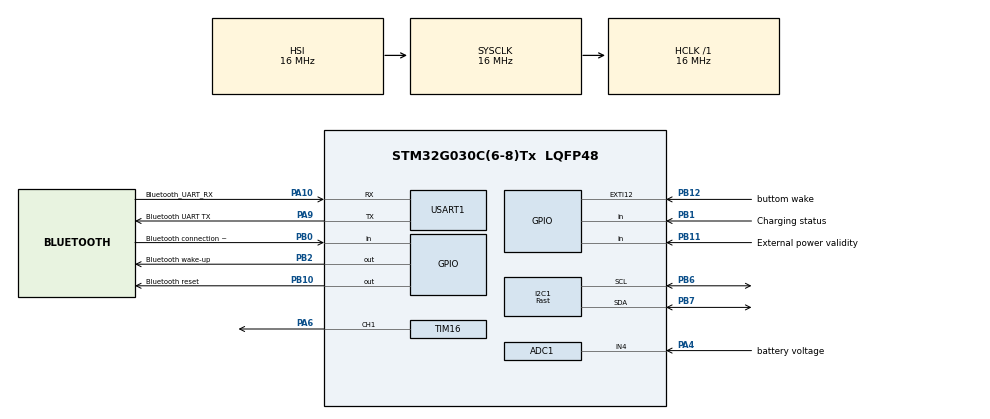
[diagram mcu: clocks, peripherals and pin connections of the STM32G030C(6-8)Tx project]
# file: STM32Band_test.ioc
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ADC1.Channel-0\#ChannelRegularConversion=ADC_CHANNEL_4
ADC1.NbrOfConversionFlag=1
ADC1.Rank-0\#ChannelRegularConversion=1
ADC1.SamplingTime-0\#ChannelRegularConversion=ADC_SAMPLINGTIME_COMMON_1
ADC1.SamplingTimeCommon1=ADC_SAMPLETIME_39CYCLES_5
ADC1.SelectedChannel=ADC_CHANNEL_4
ADC1.master=1
I2C1.I2C_Speed_Mode=I2C_Fast
I2C1.Timing=0x00300617
Mcu.Family=STM32G0
Mcu.Name=STM32G030C(6-8)Tx
Mcu.Package=LQFP48
NVIC.EXTI4_15_IRQn=true\:0\:0\:false\:false\:true\:true\:true\:true
PA10.GPIO_Label=Bluetooth_UART_RX
PA10.Mode=Asynchronous
PA10.Signal=USART1_RX
PA13.Mode=Serial_Wire
PA13.Signal=SYS_SWDIO
PA14-BOOT0.Mode=Serial_Wire
PA14-BOOT0.Signal=SYS_SWCLK
PA4.GPIO_Label=battery voltage
PA4.Mode=IN4
PA4.Signal=ADC1_IN4
PA6.Signal=S_TIM16_CH1
PA9.GPIO_Label=Bluetooth UART TX
PA9.Mode=Asynchronous
PA9.Signal=USART1_TX
PB0.GPIO_Label=Bluetooth connection status
PB0.Signal=GPIO_Input
PB1.GPIO_Label=Charging status
PB1.Signal=GPIO_Input
PB10.GPIO_Label=Bluetooth reset
PB10.PinState=GPIO_PIN_SET
PB10.Signal=GPIO_Output
PB11.GPIO_Label=External power validity
PB11.Signal=GPIO_Input
PB12.GPIO_Label=buttom wake
PB12.Signal=GPXTI12
PB2.GPIO_Label=Bluetooth wake-up
PB2.PinState=GPIO_PIN_SET
PB2.Signal=GPIO_Output
PB6.Mode=I2C
PB6.Signal=I2C1_SCL
PB7.Mode=I2C
PB7.Signal=I2C1_SDA
ProjectManager.HeapSize=0x200
ProjectManager.StackSize=0x400
ProjectManager.TargetToolchain=EWARM V8.50
RCC.AHBFreq_Value=16000000
RCC.CortexFreq_Value=16000000
RCC.EXTERNAL_CLOCK_VALUE=12288000
RCC.HCLKFreq_Value=16000000
RCC.HSE_VALUE=8000000
RCC.HSI_VALUE=16000000
RCC.LSE_VALUE=32768
RCC.SYSCLKFreq_VALUE=16000000
RCC.VCOOutputFreq_Value=128000000
SH.S_TIM16_CH1.0=TIM16_CH1,PWM Generation1 CH1
TIM16.AutoReloadPreload=TIM_AUTORELOAD_PRELOAD_ENABLE
TIM16.Channel=TIM_CHANNEL_1
TIM16.Period=3199
USART1.VirtualMode-Asynchronous=VM_ASYNC
VP_TIM16_VS_ClockSourceINT.Mode=Enable_Timer
board=custom

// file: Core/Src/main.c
/* USER CODE BEGIN Header */
/**
  ******************************************************************************
  * @file           : main.c
  * @brief          : Main program body
  ******************************************************************************
  * @attention
  *
  * Copyright (c) 2026 STMicroelectronics.
  * All rights reserved.
  *
  * This software is licensed under terms that can be found in the LICENSE file
  * in the root directory of this software component.
  * If no LICENSE file comes with this software, it is provided AS-IS.
  *
  ******************************************************************************
  */
/* USER CODE END Header */
#include "main.h"

  /* USER CODE BEGIN Includes */
#include "test_ble.h"
#include "motor.h"
/* USER CODE END Includes */

ADC_HandleTypeDef hadc1;

I2C_HandleTypeDef hi2c1;

TIM_HandleTypeDef htim16;

UART_HandleTypeDef huart1;

void SystemClock_Config(void);
static void MX_GPIO_Init(void);
static void MX_ADC1_Init(void);
static void MX_I2C1_Init(void);
static void MX_USART1_UART_Init(void);
static void MX_TIM16_Init(void);

int main(void)
{

  /* MCU Configuration--------------------------------------------------------*/

  /* Reset of all peripherals, Initializes the Flash interface and the Systick. */
  HAL_Init();

  /* USER CODE BEGIN Init */
  HAL_Delay(200);
  /* USER CODE END Init */

  /* Configure the system clock */
  SystemClock_Config();

  /* Initialize all configured peripherals */
  MX_GPIO_Init();
  MX_ADC1_Init();
  MX_I2C1_Init();
  MX_USART1_UART_Init();
  MX_TIM16_Init();
  motor_init();
  /* USER CODE BEGIN 2 */
  test_ble_main();
  /* USER CODE END 2 */

  /* Infinite loop */
  while (1)
  {

  }
}

void SystemClock_Config(void)
{
  RCC_OscInitTypeDef RCC_OscInitStruct = {0};
  RCC_ClkInitTypeDef RCC_ClkInitStruct = {0};

  /** Configure the main internal regulator output voltage
  */
  HAL_PWREx_ControlVoltageScaling(PWR_REGULATOR_VOLTAGE_SCALE1);

  /** Initializes the RCC Oscillators according to the specified parameters
  * in the RCC_OscInitTypeDef structure.
  */
  RCC_OscInitStruct.OscillatorType = RCC_OSCILLATORTYPE_HSI;
  RCC_OscInitStruct.HSIState = RCC_HSI_ON;
  RCC_OscInitStruct.HSIDiv = RCC_HSI_DIV1;
  RCC_OscInitStruct.HSICalibrationValue = RCC_HSICALIBRATION_DEFAULT;
  RCC_OscInitStruct.PLL.PLLState = RCC_PLL_NONE;
  if (HAL_RCC_OscConfig(&RCC_OscInitStruct) != HAL_OK)
  {
    Error_Handler();
  }

  /** Initializes the CPU, AHB and APB buses clocks
  */
  RCC_ClkInitStruct.ClockType = RCC_CLOCKTYPE_HCLK|RCC_CLOCKTYPE_SYSCLK
                              |RCC_CLOCKTYPE_PCLK1;
  RCC_ClkInitStruct.SYSCLKSource = RCC_SYSCLKSOURCE_HSI;
  RCC_ClkInitStruct.AHBCLKDivider = RCC_SYSCLK_DIV1;
  RCC_ClkInitStruct.APB1CLKDivider = RCC_HCLK_DIV1;

  if (HAL_RCC_ClockConfig(&RCC_ClkInitStruct, FLASH_LATENCY_0) != HAL_OK)
  {
    Error_Handler();
  }
}

static void MX_ADC1_Init(void)
{

  ADC_ChannelConfTypeDef sConfig = {0};

  /** Configure the global features of the ADC (Clock, Resolution, Data Alignment and number of conversion)
  */
  hadc1.Instance = ADC1;
  hadc1.Init.ClockPrescaler = ADC_CLOCK_SYNC_PCLK_DIV2;
  hadc1.Init.Resolution = ADC_RESOLUTION_12B;
  hadc1.Init.DataAlign = ADC_DATAALIGN_RIGHT;
  hadc1.Init.ScanConvMode = ADC_SCAN_DISABLE;
  hadc1.Init.EOCSelection = ADC_EOC_SINGLE_CONV;
  hadc1.Init.LowPowerAutoWait = DISABLE;
  hadc1.Init.LowPowerAutoPowerOff = DISABLE;
  hadc1.Init.ContinuousConvMode = DISABLE;
  hadc1.Init.NbrOfConversion = 1;
  hadc1.Init.DiscontinuousConvMode = DISABLE;
  hadc1.Init.ExternalTrigConv = ADC_SOFTWARE_START;
  hadc1.Init.ExternalTrigConvEdge = ADC_EXTERNALTRIGCONVEDGE_NONE;
  hadc1.Init.DMAContinuousRequests = DISABLE;
  hadc1.Init.Overrun = ADC_OVR_DATA_PRESERVED;
  hadc1.Init.SamplingTimeCommon1 = ADC_SAMPLETIME_39CYCLES_5;
  hadc1.Init.SamplingTimeCommon2 = ADC_SAMPLETIME_1CYCLE_5;
  hadc1.Init.OversamplingMode = DISABLE;
  hadc1.Init.TriggerFrequencyMode = ADC_TRIGGER_FREQ_HIGH;
  if (HAL_ADC_Init(&hadc1) != HAL_OK)
  {
    Error_Handler();
  }

  /** Configure Regular Channel
  */
  sConfig.Channel = ADC_CHANNEL_4;
  sConfig.Rank = ADC_REGULAR_RANK_1;
  sConfig.SamplingTime = ADC_SAMPLINGTIME_COMMON_1;
  if (HAL_ADC_ConfigChannel(&hadc1, &sConfig) != HAL_OK)
  {
    Error_Handler();
  }

}

static void MX_I2C1_Init(void)
{

  hi2c1.Instance = I2C1;
  hi2c1.Init.Timing = 0x00300617;
  hi2c1.Init.OwnAddress1 = 0;
  hi2c1.Init.AddressingMode = I2C_ADDRESSINGMODE_7BIT;
  hi2c1.Init.DualAddressMode = I2C_DUALADDRESS_DISABLE;
  hi2c1.Init.OwnAddress2 = 0;
  hi2c1.Init.OwnAddress2Masks = I2C_OA2_NOMASK;
  hi2c1.Init.GeneralCallMode = I2C_GENERALCALL_DISABLE;
  hi2c1.Init.NoStretchMode = I2C_NOSTRETCH_DISABLE;
  if (HAL_I2C_Init(&hi2c1) != HAL_OK)
  {
    Error_Handler();
  }

  /** Configure Analogue filter
  */
  if (HAL_I2CEx_ConfigAnalogFilter(&hi2c1, I2C_ANALOGFILTER_ENABLE) != HAL_OK)
  {
    Error_Handler();
  }

  /** Configure Digital filter
  */
  if (HAL_I2CEx_ConfigDigitalFilter(&hi2c1, 0) != HAL_OK)
  {
    Error_Handler();
  }

}

static void MX_TIM16_Init(void)
{

  TIM_OC_InitTypeDef sConfigOC = {0};
  TIM_BreakDeadTimeConfigTypeDef sBreakDeadTimeConfig = {0};

  htim16.Instance = TIM16;
  htim16.Init.Prescaler = 0;
  htim16.Init.CounterMode = TIM_COUNTERMODE_UP;
  htim16.Init.Period = 3199;
  htim16.Init.ClockDivision = TIM_CLOCKDIVISION_DIV1;
  htim16.Init.RepetitionCounter = 0;
  htim16.Init.AutoReloadPreload = TIM_AUTORELOAD_PRELOAD_ENABLE;
  if (HAL_TIM_Base_Init(&htim16) != HAL_OK)
  {
    Error_Handler();
  }
  if (HAL_TIM_PWM_Init(&htim16) != HAL_OK)
  {
    Error_Handler();
  }
  sConfigOC.OCMode = TIM_OCMODE_PWM1;
  sConfigOC.Pulse = 0;
  sConfigOC.OCPolarity = TIM_OCPOLARITY_HIGH;
  sConfigOC.OCNPolarity = TIM_OCNPOLARITY_HIGH;
  sConfigOC.OCFastMode = TIM_OCFAST_DISABLE;
  sConfigOC.OCIdleState = TIM_OCIDLESTATE_RESET;
  sConfigOC.OCNIdleState = TIM_OCNIDLESTATE_RESET;
  if (HAL_TIM_PWM_ConfigChannel(&htim16, &sConfigOC, TIM_CHANNEL_1) != HAL_OK)
  {
    Error_Handler();
  }
  sBreakDeadTimeConfig.OffStateRunMode = TIM_OSSR_DISABLE;
  sBreakDeadTimeConfig.OffStateIDLEMode = TIM_OSSI_DISABLE;
  sBreakDeadTimeConfig.LockLevel = TIM_LOCKLEVEL_OFF;
  sBreakDeadTimeConfig.DeadTime = 0;
  sBreakDeadTimeConfig.BreakState = TIM_BREAK_DISABLE;
  sBreakDeadTimeConfig.BreakPolarity = TIM_BREAKPOLARITY_HIGH;
  sBreakDeadTimeConfig.BreakFilter = 0;
  sBreakDeadTimeConfig.AutomaticOutput = TIM_AUTOMATICOUTPUT_DISABLE;
  if (HAL_TIMEx_ConfigBreakDeadTime(&htim16, &sBreakDeadTimeConfig) != HAL_OK)
  {
    Error_Handler();
  }
  HAL_TIM_MspPostInit(&htim16);

}

static void MX_USART1_UART_Init(void)
{

  huart1.Instance = USART1;
  huart1.Init.BaudRate = 115200;
  huart1.Init.WordLength = UART_WORDLENGTH_8B;
  huart1.Init.StopBits = UART_STOPBITS_1;
  huart1.Init.Parity = UART_PARITY_NONE;
  huart1.Init.Mode = UART_MODE_TX_RX;
  huart1.Init.HwFlowCtl = UART_HWCONTROL_NONE;
  huart1.Init.OverSampling = UART_OVERSAMPLING_16;
  huart1.Init.OneBitSampling = UART_ONE_BIT_SAMPLE_DISABLE;
  huart1.Init.ClockPrescaler = UART_PRESCALER_DIV1;
  huart1.AdvancedInit.AdvFeatureInit = UART_ADVFEATURE_NO_INIT;
  if (HAL_UART_Init(&huart1) != HAL_OK)
  {
    Error_Handler();
  }
  if (HAL_UARTEx_SetTxFifoThreshold(&huart1, UART_TXFIFO_THRESHOLD_1_8) != HAL_OK)
  {
    Error_Handler();
  }
  if (HAL_UARTEx_SetRxFifoThreshold(&huart1, UART_RXFIFO_THRESHOLD_1_8) != HAL_OK)
  {
    Error_Handler();
  }
  if (HAL_UARTEx_DisableFifoMode(&huart1) != HAL_OK)
  {
    Error_Handler();
  }

}

static void MX_GPIO_Init(void)
{
  GPIO_InitTypeDef GPIO_InitStruct = {0};

  /* GPIO Ports Clock Enable */
  __HAL_RCC_GPIOA_CLK_ENABLE();
  __HAL_RCC_GPIOB_CLK_ENABLE();

  /*Configure GPIO pin Output Level */
  HAL_GPIO_WritePin(GPIOB, Bluetooth_wake_up_Pin|Bluetooth_reset_Pin, GPIO_PIN_SET);

  /*Configure GPIO pins : Bluetooth_connection_status_Pin Charging_status_Pin External_power_validity_Pin */
  GPIO_InitStruct.Pin = Bluetooth_connection_status_Pin|Charging_status_Pin|External_power_validity_Pin;
  GPIO_InitStruct.Mode = GPIO_MODE_INPUT;
  GPIO_InitStruct.Pull = GPIO_NOPULL;
  HAL_GPIO_Init(GPIOB, &GPIO_InitStruct);

  /*Configure GPIO pins : Bluetooth_wake_up_Pin Bluetooth_reset_Pin */
  GPIO_InitStruct.Pin = Bluetooth_wake_up_Pin|Bluetooth_reset_Pin;
  GPIO_InitStruct.Mode = GPIO_MODE_OUTPUT_PP;
  GPIO_InitStruct.Pull = GPIO_NOPULL;
  GPIO_InitStruct.Speed = GPIO_SPEED_FREQ_LOW;
  HAL_GPIO_Init(GPIOB, &GPIO_InitStruct);

  /*Configure GPIO pin : buttom_wake_Pin */
  GPIO_InitStruct.Pin = buttom_wake_Pin;
  GPIO_InitStruct.Mode = GPIO_MODE_IT_RISING;
  GPIO_InitStruct.Pull = GPIO_NOPULL;
  HAL_GPIO_Init(buttom_wake_GPIO_Port, &GPIO_InitStruct);

  /* EXTI interrupt init*/
  HAL_NVIC_SetPriority(EXTI4_15_IRQn, 0, 0);
  HAL_NVIC_EnableIRQ(EXTI4_15_IRQn);

}

void Error_Handler(void)
{
  __disable_irq();
  while (1)
  {
  }
}
